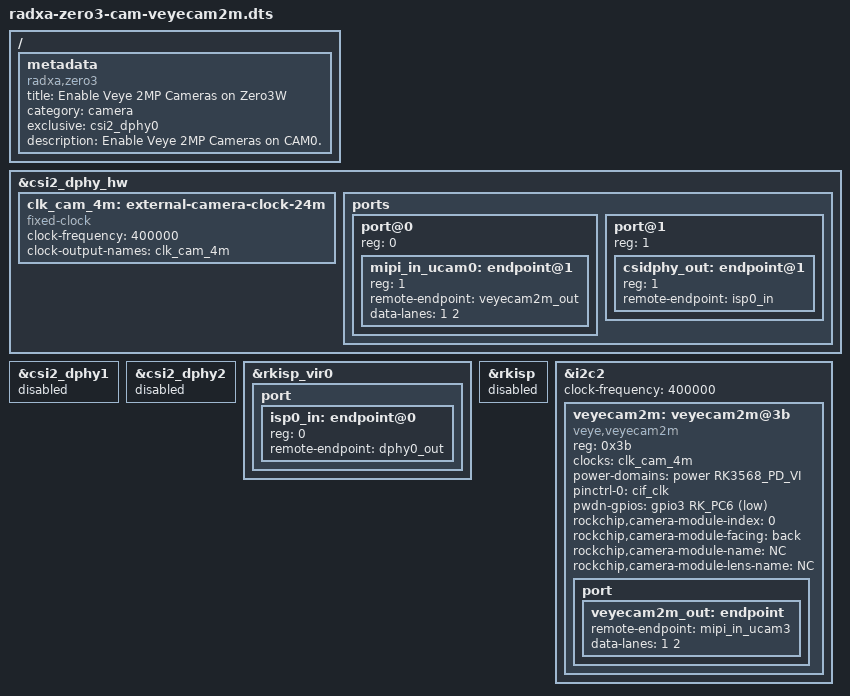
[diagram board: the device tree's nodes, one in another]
/dts-v1/;
/plugin/;

#include <dt-bindings/power/rk3568-power.h>
#include <dt-bindings/gpio/gpio.h>
#include <dt-bindings/pinctrl/rockchip.h>

/ {
	metadata {
		title = "Enable Veye 2MP Cameras on Zero3W";
		compatible = "radxa,zero3";
		category = "camera";
		exclusive = "csi2_dphy0";
		description = "Enable Veye 2MP Cameras on CAM0.";
	};
 
	fragment@0 {
		target = <&csi2_dphy_hw>;
		__overlay__ {
			status = "okay";
 
			clk_cam_4m: external-camera-clock-24m {
				status = "okay";
				compatible = "fixed-clock";
				clock-frequency = <400000>;
				clock-output-names = "clk_cam_4m";
				#clock-cells = <0>;
			};

			ports {
				#address-cells = <1>;
				#size-cells = <0>;
				port@0 {
					reg = <0>;
					#address-cells = <1>;
					#size-cells = <0>;
 
					mipi_in_ucam0: endpoint@1 {
						reg = <1>;
						remote-endpoint = <&veyecam2m_out>;
						data-lanes = <1 2>;
					};
				};
				port@1 {
					reg = <1>;
					#address-cells = <1>;
					#size-cells = <0>;
 
					csidphy_out: endpoint@1 {
						reg = <1>;
						remote-endpoint = <&isp0_in>;
					};
				};
			};
		};
	};
 
	fragment@1 {
		target = <&csi2_dphy1>;
		__overlay__ {
			status = "disabled";
		};
	};
 
	fragment@2 {
		target = <&csi2_dphy2>;
		__overlay__ {
			status = "disabled";
		};
	};
 
	fragment@3 {
		target = <&rkisp_vir0>;
		__overlay__ {
			status = "okay";
 
			port {
				#address-cells = <1>;
				#size-cells = <0>;
 
				isp0_in: endpoint@0 {
					reg = <0>;
					remote-endpoint = <&dphy0_out>;
				};
			};
		};
	};
 
	fragment@4 {
		target = <&rkisp>;
		__overlay__ {
			status = "okey";
		};
	};
 
	fragment@5 {
		target = <&i2c2>;
		__overlay__ {
			status = "okay";
			clock-frequency = <400000>;
 
			veyecam2m: veyecam2m@3b {
				status = "okay";
				compatible = "veye,veyecam2m";
				reg = <0x3b>;
				clocks = <&clk_cam_4m>;
				clock-names = "xvclk";
				//avdd-supply = <&vcc_mipi>;
				power-domains = <&power RK3568_PD_VI>;
				pinctrl-names = "default";
				pinctrl-0 = <&cif_clk>;
				pwdn-gpios = <&gpio3 RK_PC6 GPIO_ACTIVE_LOW>;

				//power-gpios = <&gpio1 RK_PC6 GPIO_ACTIVE_HIGH>;
				//reset-gpios = <&gpio3 RK_PC6 1>;
				//pwdn-gpios = <&gpio3 RK_PC6 GPIO_ACTIVE_HIGH>;
 
				rockchip,camera-module-index = <0>;
				rockchip,camera-module-facing = "back";
				rockchip,camera-module-name = "NC";
				rockchip,camera-module-lens-name = "NC";
 
				port {
					veyecam2m_out: endpoint {
						remote-endpoint = <&mipi_in_ucam3>;
						data-lanes = <1 2>;
					};
				};
			};
		};
	};
};
